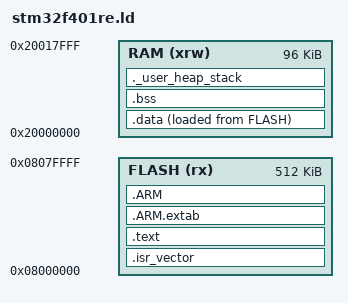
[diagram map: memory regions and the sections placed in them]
ENTRY(Reset_Handler)

MEMORY
{
  FLASH (rx)  : ORIGIN = 0x08000000, LENGTH = 512K
  RAM   (xrw) : ORIGIN = 0x20000000, LENGTH = 96K
}

_estack = ORIGIN(RAM) + LENGTH(RAM);
_min_heap  = 0x400;
_min_stack = 0x800;

SECTIONS
{
  .isr_vector : { . = ALIGN(4); KEEP(*(.isr_vector)) . = ALIGN(4); } >FLASH

  .text : {
    . = ALIGN(4);
    *(.text) *(.text*)
    *(.rodata) *(.rodata*)
    *(.glue_7) *(.glue_7t)
    KEEP(*(.init)) KEEP(*(.fini))
    . = ALIGN(4);
    _etext = .;
  } >FLASH

  .ARM.extab : { *(.ARM.extab*) } >FLASH
  .ARM       : { __exidx_start = .; *(.ARM.exidx*) __exidx_end = .; } >FLASH

  _sidata = LOADADDR(.data);

  .data : {
    . = ALIGN(4);
    _sdata = .;
    *(.data) *(.data*)
    . = ALIGN(4);
    _edata = .;
  } >RAM AT> FLASH

  .bss : {
    . = ALIGN(4);
    _sbss = .;
    __bss_start__ = _sbss;
    *(.bss) *(.bss*) *(COMMON)
    . = ALIGN(4);
    _ebss = .;
    __bss_end__ = _ebss;
  } >RAM

  ._user_heap_stack : {
    . = ALIGN(8);
    PROVIDE ( end = . );
    PROVIDE ( _end = . );
    . = . + _min_heap;
    . = . + _min_stack;
    . = ALIGN(8);
  } >RAM

  .ARM.attributes 0 : { *(.ARM.attributes) }
}
